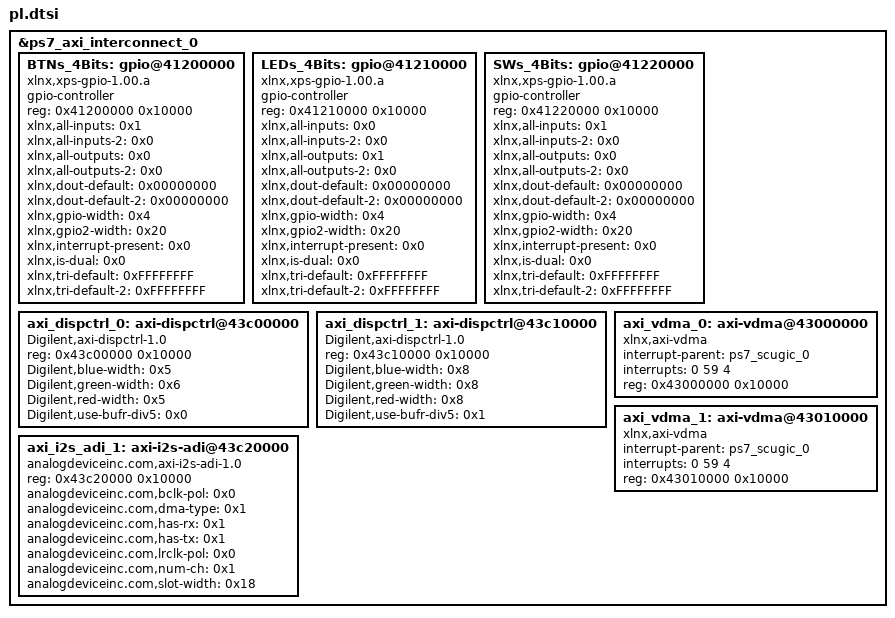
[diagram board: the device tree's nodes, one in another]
/*
 * CAUTION: This file is automatically generated by Xilinx.
 * Version:  
 * Today is: Mon Oct 13 11:46:37 2014
*/

	&ps7_axi_interconnect_0 {
		ranges;
		BTNs_4Bits: gpio@41200000 {
			#gpio-cells = <2>;
			compatible = "xlnx,xps-gpio-1.00.a";
			gpio-controller ;
			reg = <0x41200000 0x10000>;
			xlnx,all-inputs = <0x1>;
			xlnx,all-inputs-2 = <0x0>;
			xlnx,all-outputs = <0x0>;
			xlnx,all-outputs-2 = <0x0>;
			xlnx,dout-default = <0x00000000>;
			xlnx,dout-default-2 = <0x00000000>;
			xlnx,gpio-width = <0x4>;
			xlnx,gpio2-width = <0x20>;
			xlnx,interrupt-present = <0x0>;
			xlnx,is-dual = <0x0>;
			xlnx,tri-default = <0xFFFFFFFF>;
			xlnx,tri-default-2 = <0xFFFFFFFF>;
		} ;
		LEDs_4Bits: gpio@41210000 {
			#gpio-cells = <2>;
			compatible = "xlnx,xps-gpio-1.00.a";
			gpio-controller ;
			reg = <0x41210000 0x10000>;
			xlnx,all-inputs = <0x0>;
			xlnx,all-inputs-2 = <0x0>;
			xlnx,all-outputs = <0x1>;
			xlnx,all-outputs-2 = <0x0>;
			xlnx,dout-default = <0x00000000>;
			xlnx,dout-default-2 = <0x00000000>;
			xlnx,gpio-width = <0x4>;
			xlnx,gpio2-width = <0x20>;
			xlnx,interrupt-present = <0x0>;
			xlnx,is-dual = <0x0>;
			xlnx,tri-default = <0xFFFFFFFF>;
			xlnx,tri-default-2 = <0xFFFFFFFF>;
		} ;
		SWs_4Bits: gpio@41220000 {
			#gpio-cells = <2>;
			compatible = "xlnx,xps-gpio-1.00.a";
			gpio-controller ;
			reg = <0x41220000 0x10000>;
			xlnx,all-inputs = <0x1>;
			xlnx,all-inputs-2 = <0x0>;
			xlnx,all-outputs = <0x0>;
			xlnx,all-outputs-2 = <0x0>;
			xlnx,dout-default = <0x00000000>;
			xlnx,dout-default-2 = <0x00000000>;
			xlnx,gpio-width = <0x4>;
			xlnx,gpio2-width = <0x20>;
			xlnx,interrupt-present = <0x0>;
			xlnx,is-dual = <0x0>;
			xlnx,tri-default = <0xFFFFFFFF>;
			xlnx,tri-default-2 = <0xFFFFFFFF>;
		} ;
		axi_dispctrl_0: axi-dispctrl@43c00000 {
			compatible = "Digilent,axi-dispctrl-1.0";
			reg = <0x43c00000 0x10000>;
			Digilent,blue-width = <0x5>;
			Digilent,green-width = <0x6>;
			Digilent,red-width = <0x5>;
			Digilent,use-bufr-div5 = <0x0>;
		} ;
		axi_dispctrl_1: axi-dispctrl@43c10000 {
			compatible = "Digilent,axi-dispctrl-1.0";
			reg = <0x43c10000 0x10000>;
			Digilent,blue-width = <0x8>;
			Digilent,green-width = <0x8>;
			Digilent,red-width = <0x8>;
			Digilent,use-bufr-div5 = <0x1>;
		} ;
		axi_i2s_adi_1: axi-i2s-adi@43c20000 {
			compatible = "analogdeviceinc.com,axi-i2s-adi-1.0";
			reg = <0x43c20000 0x10000>;
			analogdeviceinc.com,bclk-pol = <0x0>;
			analogdeviceinc.com,dma-type = <0x1>;
			analogdeviceinc.com,has-rx = <0x1>;
			analogdeviceinc.com,has-tx = <0x1>;
			analogdeviceinc.com,lrclk-pol = <0x0>;
			analogdeviceinc.com,num-ch = <0x1>;
			analogdeviceinc.com,slot-width = <0x18>;
		} ;
		axi_vdma_0: axi-vdma@43000000 {
			compatible = "xlnx,axi-vdma";
			interrupt-parent = <&ps7_scugic_0>;
			interrupts = <0 59 4>;
			reg = <0x43000000 0x10000>;
		} ;
		axi_vdma_1: axi-vdma@43010000 {
			compatible = "xlnx,axi-vdma";
			interrupt-parent = <&ps7_scugic_0>;
			interrupts = <0 59 4>;
			reg = <0x43010000 0x10000>;
		} ;
	} ;
